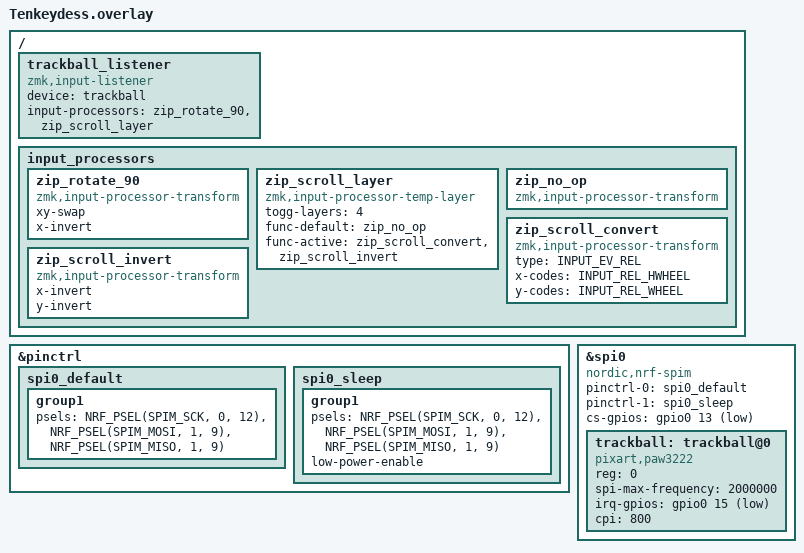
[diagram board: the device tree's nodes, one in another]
#include <dt-bindings/zmk/matrix_transform.h>
#include <dt-bindings/zmk/input_transform.h>

/* 1. ピン定義 (ユーザー提示のコード) */
&pinctrl {
    spi0_default: spi0_default {
        group1 {
            psels = <NRF_PSEL(SPIM_SCK, 0, 12)>,
                <NRF_PSEL(SPIM_MOSI, 1, 9)>,
                <NRF_PSEL(SPIM_MISO, 1, 9)>; /* 3-wire SPI setup */
        };
    };

    spi0_sleep: spi0_sleep {
        group1 {
            psels = <NRF_PSEL(SPIM_SCK, 0, 12)>,
                <NRF_PSEL(SPIM_MOSI, 1, 9)>,
                <NRF_PSEL(SPIM_MISO, 1, 9)>;
            low-power-enable;
        };
    };
};

&spi0 {
    status = "okay";
    compatible = "nordic,nrf-spim";
    pinctrl-0 = <&spi0_default>;
    pinctrl-1 = <&spi0_sleep>;
    pinctrl-names = "default", "sleep";
    cs-gpios = <&gpio0 13 GPIO_ACTIVE_LOW>;

    trackball: trackball@0 {
        status = "okay";
        compatible = "pixart,paw3222";
        reg = <0>;
        spi-max-frequency = <2000000>;
        irq-gpios = <&gpio0 15 GPIO_ACTIVE_LOW>;
        
        /* 基本感度 (必要に応じて変更) */
        cpi = <800>;
    };
};

/* 2. 入力ロジックの統合 */
/ {
    /* トラックボールのリスナー設定 */
    trackball_listener {
        compatible = "zmk,input-listener";
        device = <&trackball>;

        /* プロセッサのチェーン順序:
           1. 90度回転補正
           2. レイヤーによるスクロール切替 & 反転
        */
        input-processors = <&zip_rotate_90 &zip_scroll_layer>;
    };

    input_processors {
        /* 【90度回転】 XY入替 + X反転 (時計回り90度想定) */
        zip_rotate_90: zip_rotate_90 {
            compatible = "zmk,input-processor-transform";
            xy-swap;
            x-invert;
        };

        /* 【スクロールレイヤー】 */
        zip_scroll_layer: zip_scroll_layer {
            compatible = "zmk,input-processor-temp-layer";
            
            /* スクロールを有効にするレイヤー番号 (要調整) */
            togg-layers = <4>; 

            /* 通常時: そのまま通す */
            func-default = <&zip_no_op>;
            
            /* レイヤーON時: マウス移動をスクロールに変換 + 反転 */
            func-active = <&zip_scroll_convert &zip_scroll_invert>;
        };

        /* 何もしないプロセッサ */
        zip_no_op: zip_no_op {
            compatible = "zmk,input-processor-transform";
        };

        /* 移動 -> スクロール変換 */
        zip_scroll_convert: zip_scroll_convert {
            compatible = "zmk,input-processor-transform";
            type = <INPUT_EV_REL>;
            x-codes = <INPUT_REL_HWHEEL>;
            y-codes = <INPUT_REL_WHEEL>;
        };

        /* スクロール反転 */
        zip_scroll_invert: zip_scroll_invert {
            compatible = "zmk,input-processor-transform";
            x-invert;
            y-invert;
        };
    };
};
